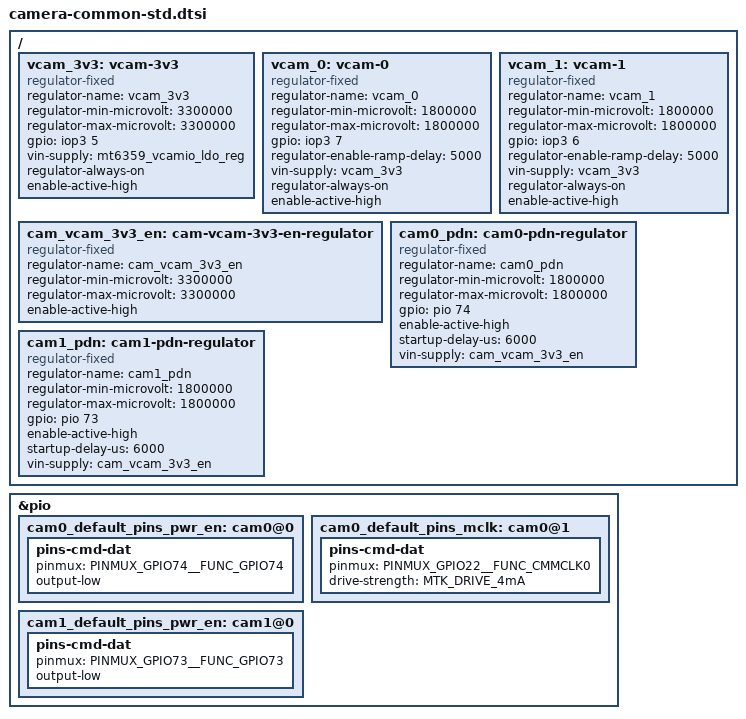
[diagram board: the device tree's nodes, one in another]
// SPDX-License-Identifier: GPL-2.0
/*
 * Copyright (c) 2025 MediaTek Inc.
 *
 */

#include <dt-bindings/gpio/gpio.h>
#include <dt-bindings/pinctrl/mt8189-pinfunc.h>

/ {
	fragment@1 {
		target-path = "/";
		__overlay__ {
			/* 
				workaround:
				for cyberdeck hw r1.0, vcam1 power shared with mipi-lcd,
				so it can't be turn off.
			*/

			vcam_3v3: vcam-3v3 {
				compatible = "regulator-fixed";
				regulator-name = "vcam_3v3";
				regulator-min-microvolt = <3300000>;
				regulator-max-microvolt = <3300000>;
				gpio = <&iop3 5 GPIO_ACTIVE_HIGH>;
				vin-supply = <&mt6359_vcamio_ldo_reg>;
				regulator-always-on;
				enable-active-high;
			};

			vcam_0: vcam-0 {
				compatible = "regulator-fixed";
				regulator-name = "vcam_0";
				regulator-min-microvolt = <1800000>;
				regulator-max-microvolt = <1800000>;
				gpio = <&iop3 7 GPIO_ACTIVE_HIGH>;
				regulator-enable-ramp-delay = <5000>;
				vin-supply = <&vcam_3v3>;
				regulator-always-on;
				enable-active-high;
			};

			vcam_1: vcam-1 {
				compatible = "regulator-fixed";
				regulator-name = "vcam_1";
				regulator-min-microvolt = <1800000>;
				regulator-max-microvolt = <1800000>;
				gpio = <&iop3 6 GPIO_ACTIVE_HIGH>;
				regulator-enable-ramp-delay = <5000>;
				vin-supply = <&vcam_3v3>;
				regulator-always-on;
				enable-active-high;
			};

			cam_vcam_3v3_en: cam-vcam-3v3-en-regulator {
				compatible = "regulator-fixed";
				regulator-name = "cam_vcam_3v3_en";
				regulator-min-microvolt = <3300000>;
				regulator-max-microvolt = <3300000>;
				enable-active-high;
			};

			cam0_pdn: cam0-pdn-regulator {
				compatible = "regulator-fixed";
				regulator-name = "cam0_pdn";
				regulator-min-microvolt = <1800000>;
				regulator-max-microvolt = <1800000>;
				gpio = <&pio 74 0>;
				enable-active-high;
				startup-delay-us = <6000>;
				vin-supply = <&cam_vcam_3v3_en>;
			};

			cam1_pdn: cam1-pdn-regulator {
				compatible = "regulator-fixed";
				regulator-name = "cam1_pdn";
				regulator-min-microvolt = <1800000>;
				regulator-max-microvolt = <1800000>;
				gpio = <&pio 73 0>;
				enable-active-high;
				startup-delay-us = <6000>;
				vin-supply = <&cam_vcam_3v3_en>;
			};
		};
	};

	fragment@2 {
		target = <&pio>;
		__overlay__ {
			cam0_default_pins_pwr_en: cam0@0 {
				pins-cmd-dat {
					pinmux = <PINMUX_GPIO74__FUNC_GPIO74>;
					output-low;
				};
			};
			cam0_default_pins_mclk: cam0@1 {
				pins-cmd-dat {
					pinmux = <PINMUX_GPIO22__FUNC_CMMCLK0>;
					drive-strength = <MTK_DRIVE_4mA>;
				};
			};

			cam1_default_pins_pwr_en: cam1@0 {
				pins-cmd-dat {
					pinmux = <PINMUX_GPIO73__FUNC_GPIO73>;
					output-low;
				};
			};
		};
	};
};
